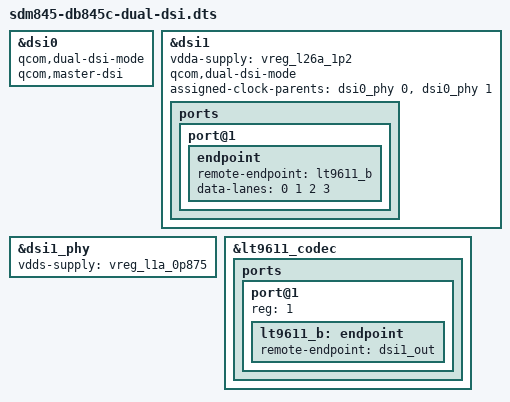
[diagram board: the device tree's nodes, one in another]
// SPDX-License-Identifier: GPL-2.0
/*
 * Copyright (c) 2023, Linaro Ltd.
 */

#include "sdm845-db845c.dts"

&dsi0 {
	qcom,dual-dsi-mode;
	qcom,master-dsi;
};

&dsi1 {
	vdda-supply = <&vreg_l26a_1p2>;

	qcom,dual-dsi-mode;

	/* DSI1 is slave, so use DSI0 clocks */
	assigned-clock-parents = <&dsi0_phy 0>, <&dsi0_phy 1>;

	status = "okay";

	ports {
		port@1 {
			endpoint {
				remote-endpoint = <&lt9611_b>;
				data-lanes = <0 1 2 3>;
			};
		};
	};
};

&dsi1_phy {
	vdds-supply = <&vreg_l1a_0p875>;
	status = "okay";
};

&lt9611_codec {
	ports {
		port@1 {
			reg = <1>;

			lt9611_b: endpoint {
				remote-endpoint = <&dsi1_out>;
			};
		};
	};
};
